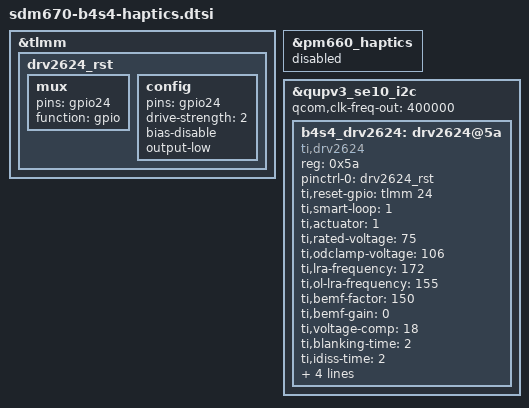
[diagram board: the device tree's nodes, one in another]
/* Copyright (c) 2018, The Linux Foundation. All rights reserved.
 *
 * This program is free software; you can redistribute it and/or modify
 * it under the terms of the GNU General Public License version 2 and
 * only version 2 as published by the Free Software Foundation.
 *
 * This program is distributed in the hope that it will be useful,
 * but WITHOUT ANY WARRANTY; without even the implied warranty of
 * MERCHANTABILITY or FITNESS FOR A PARTICULAR PURPOSE. See the
 * GNU General Public License for more details.
 */

&tlmm {
	drv2624_rst: drv2624_rst {
		mux {
			pins = "gpio24";
			function = "gpio";
		};
		config {
			pins = "gpio24";
			drive-strength = <2>;
			bias-disable;
			output-low;
		};
	};
};

&pm660_haptics {
	status = "disabled";
};

&qupv3_se10_i2c {
	status = "okay";
	qcom,clk-freq-out = <400000>;
	b4s4_drv2624: drv2624@5a {
		compatible = "ti,drv2624";
		reg = <0x5a>;
		pinctrl-names = "default";
		pinctrl-0 = <&drv2624_rst>;
		ti,reset-gpio = <&tlmm 24 0>;
		ti,smart-loop = <1>; /* 0-closeloop, 1-openloop */
		ti,actuator = <1>; /* 0-ERM, 1-LRA */
		ti,rated-voltage = <75>;
		ti,odclamp-voltage = <106>; /* 2.1 Vrms */
		ti,lra-frequency = <172>; /* f0 = 172Hz */
		ti,ol-lra-frequency = <155>; /* off-f0 in OL */
		ti,bemf-factor = <150>;
		ti,bemf-gain = <0>;
		ti,voltage-comp = <18>;
		ti,blanking-time = <2>; /* 50 us */
		ti,idiss-time = <2>; /* 50 us */
		ti,zc-det-time = <0>; /* 100 us*/
		ti,lra-wave-shape = <0>; /* Square wave */
		ti,waveform-interval = <1>; /* 1 ms */
		ti,fb-brake-factor = <0>; /* braking factor 1 */
		status = "ok";
	};
};
